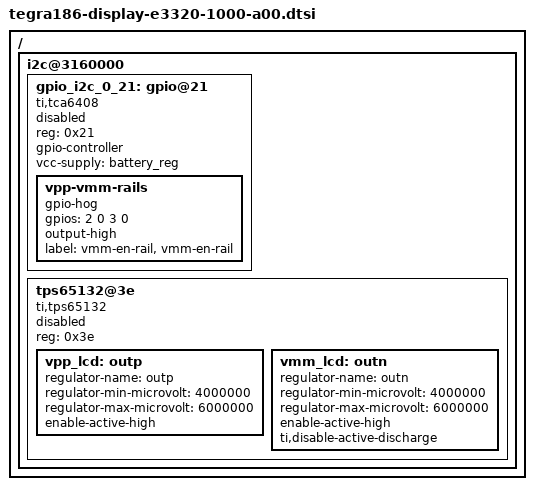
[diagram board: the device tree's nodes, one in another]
/*
 * Copyright (c) 2015-2017, NVIDIA CORPORATION.  All rights reserved.
 *
 * This program is free software; you can redistribute it and/or modify
 * it under the terms of the GNU General Public License as published by
 * the Free Software Foundation; either version 2 of the License, or
 * (at your option) any later version.
 *
 * This program is distributed in the hope that it will be useful, but WITHOUT
 * ANY WARRANTY; without even the implied warranty of MERCHANTABILITY or
 * FITNESS FOR A PARTICULAR PURPOSE.  See the GNU General Public License for
 * more details.
 *
 * You should have received a copy of the GNU General Public License
 * along with this program.  If not, see <http://www.gnu.org/licenses/>.
 */

#include <dt-bindings/gpio/tegra186-gpio.h>
#include <dt-bindings/spi/lr388k7_platform.h>
/ {

	i2c@3160000 {
		gpio_i2c_0_21: gpio@21 {
			compatible = "ti,tca6408";
			status = "disabled";
			reg = <0x21>;
			gpio-controller;
			#gpio-cells = <2>;
			vcc-supply = <&battery_reg>;
			vpp-vmm-rails {
				gpio-hog;
				gpios = <2 0 3 0>;
				output-high;
				label = "vmm-en-rail", "vmm-en-rail";
			};
		};

		/* outp,outn enable gpios set through plugin manager dt */
		tps65132@3e {
			reg = <0x3e>;
			compatible = "ti,tps65132";
			status = "disabled";
			vpp_lcd: outp {
				regulator-name = "outp";
				regulator-min-microvolt = <4000000>;
				regulator-max-microvolt = <6000000>;
				enable-active-high;
			};

			vmm_lcd: outn {
				regulator-name = "outn";
				regulator-min-microvolt = <4000000>;
				regulator-max-microvolt = <6000000>;
				enable-active-high;
				ti,disable-active-discharge;
			};
		};
	};
};
